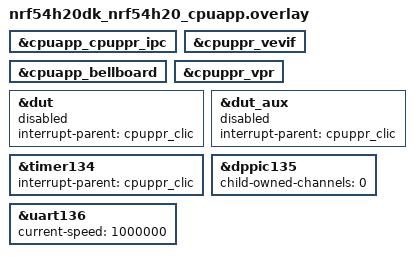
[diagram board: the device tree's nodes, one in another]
/* SPDX-License-Identifier: Apache-2.0 */

#include "../../../boards/nrf54h20dk_nrf54h20_common.dtsi"

&cpuapp_cpuppr_ipc {
	status = "okay";
};

&cpuppr_vevif {
	status = "okay";
};

&cpuapp_bellboard {
	status = "okay";
};

&cpuppr_vpr {
	status = "okay";
};

&dut {
	status = "reserved";
	interrupt-parent = <&cpuppr_clic>;
};

&dut_aux {
	status = "reserved";
	interrupt-parent = <&cpuppr_clic>;
};

&timer134 {
	interrupt-parent = <&cpuppr_clic>;
};

&dppic135 {
	child-owned-channels = <0>;
};

&uart136 {
	current-speed = <1000000>;
};
